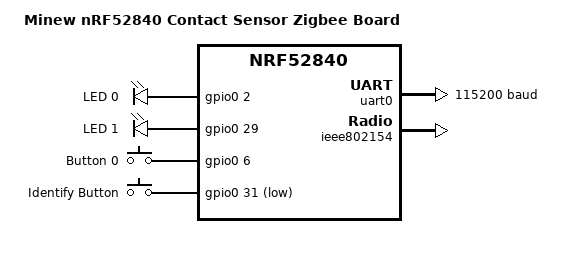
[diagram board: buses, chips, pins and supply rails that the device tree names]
// Copyright (c) 2024 Nordic Semiconductor ASA
// SPDX-License-Identifier: Apache-2.0

/dts-v1/;
#include <nordic/nrf52840_qiaa.dtsi>
#include "minew_nrf52840_contact-pinctrl.dtsi"
#include <zephyr/dt-bindings/input/input-event-codes.h>

/ {
	model = "Minew nRF52840 Contact Sensor Zigbee Board";
	compatible = "minew,minew-nrf52840-contact";

	chosen {
		zephyr,console = &uart0;
		zephyr,shell-uart = &uart0;
		zephyr,bt-mon-uart = &uart0;
		zephyr,bt-c2h-uart = &uart0;
		zephyr,sram = &sram0;
		zephyr,flash = &flash0;
		zephyr,code-partition = &slot0_partition;
		zephyr,ieee802154 = &ieee802154;
	};

	leds {
		compatible = "gpio-leds";
		led0: led_0 {
			gpios = <&gpio0 2 GPIO_ACTIVE_HIGH>;
			label = "LED 0";
		};
		compatible = "gpio-leds";
		led1: led_1 {
			gpios = <&gpio0 29 GPIO_ACTIVE_HIGH>;
			label = "LED 1";
		};
	};

	buttons {
		compatible = "gpio-keys";
		button0: button_0 {
			gpios = <&gpio0 6 (GPIO_ACTIVE_HIGH)>;
			label = "Button 0";
			zephyr,code = <INPUT_KEY_0>;
		};
		button1: button_1 {
			gpios = <&gpio0 31 (GPIO_PULL_UP | GPIO_ACTIVE_LOW)>;
			label = "Identify Button";
			zephyr,code = <INPUT_KEY_1>;
		};
	};

	aliases {
		led0 = &led0;
		led1 = &led1;
		sw0 = &button0;
		sw1 = &button1;
		watchdog0 = &wdt0;
	};
};

&uicr {
	gpio-as-nreset;
};

&gpiote {
	status = "okay";
};

&gpio0 {
	status = "okay";
};

&uart0 {
	compatible = "nordic,nrf-uart";
	current-speed = <115200>;
	status = "okay";
	pinctrl-0 = <&uart0_default>;
	pinctrl-1 = <&uart0_sleep>;
	pinctrl-names = "default", "sleep";
};

&ieee802154 {
        status = "okay";
};

&flash0 {
	partitions {
		compatible = "fixed-partitions";
		#address-cells = <1>;
		#size-cells = <1>;

		boot_partition: partition@0 {
			label = "mcuboot";
			reg = <0x0 0xc000>;
		};
		slot0_partition: partition@c000 {
			label = "image-0";
			reg = <0xc000 0x72000>;
		};
		slot1_partition: partition@7e000 {
			label = "image-1";
			reg = <0x7e000 0x72000>;
		};
		scratch_partition: partition@f0000 {
			label = "image-scratch";
			reg = <0xf0000 0xa000>;
		};
		storage_partition: partition@fa000 {
			label = "storage";
			reg = <0xfa000 0x6000>;
		};
	};
};

